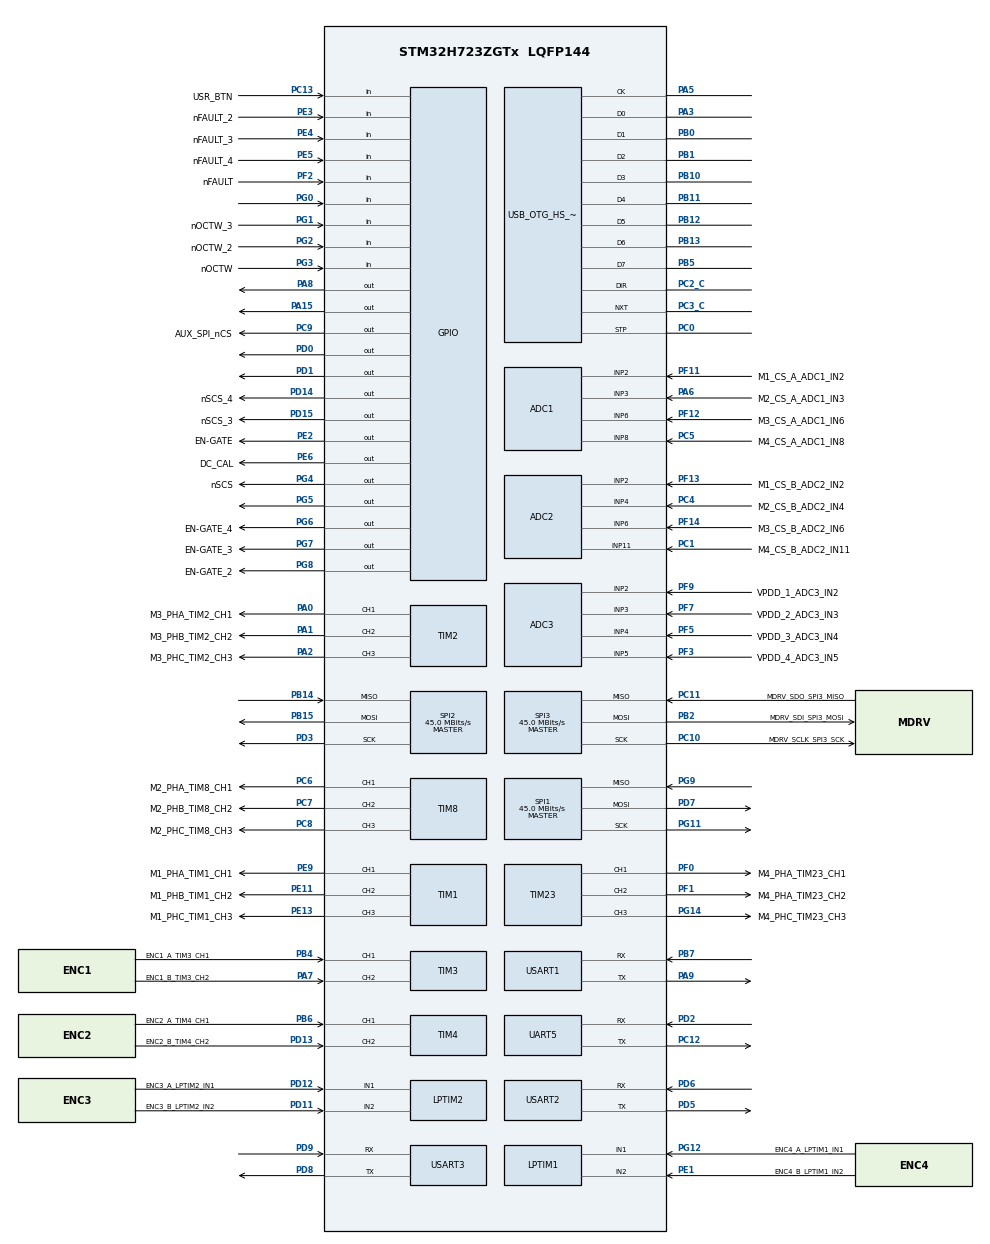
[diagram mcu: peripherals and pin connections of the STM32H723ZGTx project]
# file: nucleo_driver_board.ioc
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ADC1.Channel-0\#ChannelRegularConversion=ADC_CHANNEL_2
ADC1.ClockPrescaler=ADC_CLOCK_ASYNC_DIV4
ADC1.NbrOfConversionFlag=1
ADC1.OffsetNumber-0\#ChannelRegularConversion=ADC_OFFSET_NONE
ADC1.OffsetSignedSaturation-0\#ChannelRegularConversion=DISABLE
ADC1.Rank-0\#ChannelRegularConversion=1
ADC1.SamplingTime-0\#ChannelRegularConversion=ADC_SAMPLETIME_1CYCLE_5
ADC1.master=1
ADC2.Channel-4\#ChannelRegularConversion=ADC_CHANNEL_6
ADC2.ClockPrescaler=ADC_CLOCK_ASYNC_DIV4
ADC2.NbrOfConversionFlag=1
ADC2.OffsetNumber-4\#ChannelRegularConversion=ADC_OFFSET_NONE
ADC2.OffsetSignedSaturation-4\#ChannelRegularConversion=DISABLE
ADC2.Rank-4\#ChannelRegularConversion=1
ADC2.SamplingTime-4\#ChannelRegularConversion=ADC_SAMPLETIME_1CYCLE_5
ADC3.Channel-1\#ChannelRegularConversion=ADC_CHANNEL_2
ADC3.NbrOfConversionFlag=1
ADC3.OffsetNumber-1\#ChannelRegularConversion=ADC_OFFSET_NONE
ADC3.OffsetSign-1\#ChannelRegularConversion=ADC3_OFFSET_SIGN_NEGATIVE
ADC3.Rank-1\#ChannelRegularConversion=1
ADC3.SamplingTime-1\#ChannelRegularConversion=ADC3_SAMPLETIME_2CYCLES_5
Mcu.Family=STM32H7
Mcu.Name=STM32H723ZGTx
Mcu.Package=LQFP144
NVIC.OTG_HS_EP1_IN_IRQn=true\:0\:0\:false\:false\:true\:true\:true\:true
NVIC.OTG_HS_EP1_OUT_IRQn=true\:0\:0\:false\:false\:true\:true\:true\:true
NVIC.OTG_HS_IRQn=true\:0\:0\:false\:false\:true\:false\:true\:true
NVIC.PriorityGroup=NVIC_PRIORITYGROUP_4
PA0.GPIO_Label=M3_PHA_TIM2_CH1
PA0.Signal=S_TIM2_CH1_ETR
PA1.GPIO_Label=M3_PHB_TIM2_CH2
PA1.Signal=S_TIM2_CH2
PA13(JTMS/SWDIO).Mode=Trace_Asynchronous_SW
PA13(JTMS/SWDIO).Signal=DEBUG_JTMS-SWDIO
PA14(JTCK/SWCLK).Mode=Trace_Asynchronous_SW
PA14(JTCK/SWCLK).Signal=DEBUG_JTCK-SWCLK
PA15(JTDI).Signal=GPIO_Output
PA2.GPIO_Label=M3_PHC_TIM2_CH3
PA2.Signal=S_TIM2_CH3
PA3.Mode=Device_HS
PA3.Signal=USB_OTG_HS_ULPI_D0
PA5.Mode=Device_HS
PA5.Signal=USB_OTG_HS_ULPI_CK
PA6.GPIO_Label=M2_CS_A_ADC1_IN3
PA6.Signal=ADCx_INP3
PA7.GPIO_Label=ENC1_B_TIM3_CH2
PA7.Signal=S_TIM3_CH2
PA8.Signal=GPIO_Output
PA9.Mode=Asynchronous
PA9.Signal=USART1_TX
PB0.Mode=Device_HS
PB0.Signal=USB_OTG_HS_ULPI_D1
PB1.Mode=Device_HS
PB1.Signal=USB_OTG_HS_ULPI_D2
PB10.Mode=Device_HS
PB10.Signal=USB_OTG_HS_ULPI_D3
PB11.Mode=Device_HS
PB11.Signal=USB_OTG_HS_ULPI_D4
PB12.Mode=Device_HS
PB12.Signal=USB_OTG_HS_ULPI_D5
PB13.Mode=Device_HS
PB13.Signal=USB_OTG_HS_ULPI_D6
PB14.Mode=Full_Duplex_Master
PB14.Signal=SPI2_MISO
PB15.Mode=Full_Duplex_Master
PB15.Signal=SPI2_MOSI
PB2.GPIO_Label=MDRV_SDI_SPI3_MOSI
PB2.Mode=Full_Duplex_Master
PB2.Signal=SPI3_MOSI
PB3(JTDO/TRACESWO).Mode=Trace_Asynchronous_SW
PB3(JTDO/TRACESWO).Signal=DEBUG_JTDO-SWO
PB4(NJTRST).GPIO_Label=ENC1_A_TIM3_CH1
PB4(NJTRST).Signal=S_TIM3_CH1
PB5.Mode=Device_HS
PB5.Signal=USB_OTG_HS_ULPI_D7
PB6.GPIO_Label=ENC2_A_TIM4_CH1
PB6.Signal=S_TIM4_CH1
PB7.Mode=Asynchronous
PB7.Signal=USART1_RX
PC0.Mode=Device_HS
PC0.Signal=USB_OTG_HS_ULPI_STP
PC1.GPIO_Label=M4_CS_B_ADC2_IN11
PC1.Signal=ADCx_INP11
PC10.GPIO_Label=MDRV_SCLK_SPI3_SCK
PC10.Mode=Full_Duplex_Master
PC10.Signal=SPI3_SCK
PC11.GPIO_Label=MDRV_SDO_SPI3_MISO
PC11.Mode=Full_Duplex_Master
PC11.Signal=SPI3_MISO
PC12.Mode=Asynchronous
PC12.Signal=UART5_TX
PC13.GPIO_Label=USR_BTN
PC13.Signal=GPIO_Input
PC2_C.Mode=Device_HS
PC2_C.Signal=USB_OTG_HS_ULPI_DIR
PC3_C.Mode=Device_HS
PC3_C.Signal=USB_OTG_HS_ULPI_NXT
PC4.GPIO_Label=M2_CS_B_ADC2_IN4
PC4.Signal=ADCx_INP4
PC5.GPIO_Label=M4_CS_A_ADC1_IN8
PC5.Signal=ADCx_INP8
PC6.GPIO_Label=M2_PHA_TIM8_CH1
PC6.Signal=S_TIM8_CH1
PC7.GPIO_Label=M2_PHB_TIM8_CH2
PC7.Signal=S_TIM8_CH2
PC8.GPIO_Label=M2_PHC_TIM8_CH3
PC8.Signal=S_TIM8_CH3
PC9.GPIO_Label=AUX_SPI_nCS
PC9.Signal=GPIO_Output
PD0.Signal=GPIO_Output
PD1.Signal=GPIO_Output
PD11.GPIO_Label=ENC3_B_LPTIM2_IN2
PD11.Mode=Encoder_mode_occur1
PD11.Signal=LPTIM2_IN2
PD12.GPIO_Label=ENC3_A_LPTIM2_IN1
PD12.Mode=Encoder_mode_occur1
PD12.Signal=LPTIM2_IN1
PD13.GPIO_Label=ENC2_B_TIM4_CH2
PD13.Signal=S_TIM4_CH2
PD14.GPIO_Label=nSCS_4
PD14.Signal=GPIO_Output
PD15.GPIO_Label=nSCS_3
PD15.Signal=GPIO_Output
PD2.Mode=Asynchronous
PD2.Signal=UART5_RX
PD3.Mode=Full_Duplex_Master
PD3.Signal=SPI2_SCK
PD5.Mode=Asynchronous
PD5.Signal=USART2_TX
PD6.Mode=Asynchronous
PD6.Signal=USART2_RX
PD7.Mode=Full_Duplex_Master
PD7.Signal=SPI1_MOSI
PD8.Mode=Asynchronous
PD8.Signal=USART3_TX
PD9.Mode=Asynchronous
PD9.Signal=USART3_RX
PE1.GPIO_Label=ENC4_B_LPTIM1_IN2
PE1.Mode=Encoder_mode_occur1
PE1.Signal=LPTIM1_IN2
PE11.GPIO_Label=M1_PHB_TIM1_CH2
PE11.Signal=S_TIM1_CH2
PE13.GPIO_Label=M1_PHC_TIM1_CH3
PE13.Signal=S_TIM1_CH3
PE2.GPIO_Label=EN-GATE
PE2.Signal=GPIO_Output
PE3.GPIO_Label=nFAULT_2
PE3.Signal=GPIO_Input
PE4.GPIO_Label=nFAULT_3
PE4.Signal=GPIO_Input
PE5.GPIO_Label=nFAULT_4
PE5.Signal=GPIO_Input
PE6.GPIO_Label=DC_CAL
PE6.Signal=GPIO_Output
PE9.GPIO_Label=M1_PHA_TIM1_CH1
PE9.Signal=S_TIM1_CH1
PF0.GPIO_Label=M4_PHA_TIM23_CH1
PF0.Mode=PWM Generation1 CH1
PF0.Signal=TIM23_CH1
PF1.GPIO_Label=M4_PHA_TIM23_CH2
PF1.Signal=S_TIM23_CH2
PF11.GPIO_Label=M1_CS_A_ADC1_IN2
PF11.Mode=IN2-Single-Ended
PF11.Signal=ADC1_INP2
PF12.GPIO_Label=M3_CS_A_ADC1_IN6
PF12.Mode=IN6-Single-Ended
PF12.Signal=ADC1_INP6
PF13.GPIO_Label=M1_CS_B_ADC2_IN2
PF13.Mode=IN2-Single-Ended
PF13.Signal=ADC2_INP2
PF14.GPIO_Label=M3_CS_B_ADC2_IN6
PF14.Mode=IN6-Single-Ended
PF14.Signal=ADC2_INP6
PF2.GPIO_Label=nFAULT
PF2.Signal=GPIO_Input
PF3.GPIO_Label=VPDD_4_ADC3_IN5
PF3.Mode=IN5-Single-Ended
PF3.Signal=ADC3_INP5
PF5.GPIO_Label=VPDD_3_ADC3_IN4
PF5.Mode=IN4-Single-Ended
PF5.Signal=ADC3_INP4
PF7.GPIO_Label=VPDD_2_ADC3_IN3
PF7.Mode=IN3-Single-Ended
PF7.Signal=ADC3_INP3
PF9.GPIO_Label=VPDD_1_ADC3_IN2
PF9.Mode=IN2-Single-Ended
PF9.Signal=ADC3_INP2
PG0.Signal=GPIO_Input
PG1.GPIO_Label=nOCTW_3
PG1.Signal=GPIO_Input
PG11.Mode=Full_Duplex_Master
PG11.Signal=SPI1_SCK
PG12.GPIO_Label=ENC4_A_LPTIM1_IN1
PG12.Mode=Encoder_mode_occur1
PG12.Signal=LPTIM1_IN1
PG14.GPIO_Label=M4_PHC_TIM23_CH3
PG14.Signal=S_TIM23_CH3
PG2.GPIO_Label=nOCTW_2
PG2.Signal=GPIO_Input
PG3.GPIO_Label=nOCTW
PG3.Signal=GPIO_Input
PG4.GPIO_Label=nSCS
PG4.Signal=GPIO_Output
PG5.Signal=GPIO_Output
PG6.GPIO_Label=EN-GATE_4
PG6.Signal=GPIO_Output
PG7.GPIO_Label=EN-GATE_3
PG7.Signal=GPIO_Output
PG8.GPIO_Label=EN-GATE_2
PG8.Signal=GPIO_Output
PG9.Mode=Full_Duplex_Master
PG9.Signal=SPI1_MISO
ProjectManager.HeapSize=0x200
ProjectManager.StackSize=0x400
ProjectManager.TargetToolchain=Makefile
RCC.ADCFreq_Value=90000000
RCC.APB1Freq_Value=136000000
RCC.APB2Freq_Value=136000000
RCC.APB3Freq_Value=136000000
RCC.APB4Freq_Value=136000000
RCC.CortexFreq_Value=544000000
RCC.D1PPRE=RCC_APB3_DIV2
RCC.D2PPRE1=RCC_APB1_DIV2
RCC.D2PPRE2=RCC_APB2_DIV2
RCC.D3PPRE=RCC_APB4_DIV2
RCC.DIVM1=4
RCC.DIVM2=4
RCC.DIVN1=34
RCC.DIVN2=45
RCC.DIVP1=1
RCC.DIVP2=8
RCC.DIVQ1=3
RCC.HCLKFreq_Value=272000000
RCC.HPRE=RCC_HCLK_DIV2
RCC.LPTIM1CLockSelection=RCC_LPTIM1CLKSOURCE_PLL2
RCC.LPTIM2CLockSelection=RCC_LPTIM2CLKSOURCE_PLL2
RCC.PLL2FRACN=0
RCC.PLL3FRACN=0
RCC.PLLFRACN=0
RCC.RCC_MCO1Source=RCC_MCO1SOURCE_HSI48
RCC.RCC_MCODiv1=RCC_MCODIV_2
RCC.SPI123CLockSelection=RCC_SPI123CLKSOURCE_PLL2
RCC.SYSCLKFreq_VALUE=544000000
RCC.SYSCLKSource=RCC_SYSCLKSOURCE_PLLCLK
RCC.USART16CLockSelection=RCC_USART16910CLKSOURCE_HSI
RCC.USART234578CLockSelection=RCC_USART234578CLKSOURCE_HSI
RCC.USBCLockSelection=RCC_USBCLKSOURCE_HSI48
RCC.USBFreq_Value=48000000
SH.ADCx_INP11.0=ADC2_INP11,IN11-Single-Ended
SH.ADCx_INP3.0=ADC1_INP3,IN3-Single-Ended
SH.ADCx_INP4.0=ADC2_INP4,IN4-Single-Ended
SH.ADCx_INP8.0=ADC1_INP8,IN8-Single-Ended
SH.S_TIM1_CH1.0=TIM1_CH1,PWM Generation1 CH1
SH.S_TIM1_CH2.0=TIM1_CH2,PWM Generation2 CH2
SH.S_TIM1_CH3.0=TIM1_CH3,PWM Generation3 CH3
SH.S_TIM23_CH2.0=TIM23_CH2,PWM Generation2 CH2
SH.S_TIM23_CH3.0=TIM23_CH3,PWM Generation3 CH3
SH.S_TIM2_CH1_ETR.0=TIM2_CH1,PWM Generation1 CH1
SH.S_TIM2_CH2.0=TIM2_CH2,PWM Generation2 CH2
SH.S_TIM2_CH3.0=TIM2_CH3,PWM Generation3 CH3
SH.S_TIM3_CH1.0=TIM3_CH1,Encoder_Interface
SH.S_TIM3_CH2.0=TIM3_CH2,Encoder_Interface
SH.S_TIM4_CH1.0=TIM4_CH1,Encoder_Interface
SH.S_TIM4_CH2.0=TIM4_CH2,Encoder_Interface
SH.S_TIM8_CH1.0=TIM8_CH1,PWM Generation1 CH1
SH.S_TIM8_CH2.0=TIM8_CH2,PWM Generation2 CH2
SH.S_TIM8_CH3.0=TIM8_CH3,PWM Generation3 CH3
SPI1.BaudRatePrescaler=SPI_BAUDRATEPRESCALER_2
SPI1.CalculateBaudRate=45.0 MBits/s
SPI1.Direction=SPI_DIRECTION_2LINES
SPI1.Mode=SPI_MODE_MASTER
SPI1.VirtualType=VM_MASTER
SPI2.BaudRatePrescaler=SPI_BAUDRATEPRESCALER_2
SPI2.CalculateBaudRate=45.0 MBits/s
SPI2.Direction=SPI_DIRECTION_2LINES
SPI2.Mode=SPI_MODE_MASTER
SPI2.VirtualType=VM_MASTER
SPI3.BaudRatePrescaler=SPI_BAUDRATEPRESCALER_2
SPI3.CalculateBaudRate=45.0 MBits/s
SPI3.Direction=SPI_DIRECTION_2LINES
SPI3.Mode=SPI_MODE_MASTER
SPI3.VirtualType=VM_MASTER
TIM1.Channel-PWM\ Generation1\ CH1=TIM_CHANNEL_1
TIM1.Channel-PWM\ Generation2\ CH2=TIM_CHANNEL_2
TIM1.Channel-PWM\ Generation3\ CH3=TIM_CHANNEL_3
TIM2.Channel-PWM\ Generation1\ CH1=TIM_CHANNEL_1
TIM2.Channel-PWM\ Generation2\ CH2=TIM_CHANNEL_2
TIM2.Channel-PWM\ Generation3\ CH3=TIM_CHANNEL_3
TIM23.Channel-PWM\ Generation1\ CH1=TIM_CHANNEL_1
TIM23.Channel-PWM\ Generation2\ CH2=TIM_CHANNEL_2
TIM23.Channel-PWM\ Generation3\ CH3=TIM_CHANNEL_3
TIM3.EncoderMode=TIM_ENCODERMODE_TI12
TIM4.EncoderMode=TIM_ENCODERMODE_TI12
TIM8.Channel-PWM\ Generation1\ CH1=TIM_CHANNEL_1
TIM8.Channel-PWM\ Generation2\ CH2=TIM_CHANNEL_2
TIM8.Channel-PWM\ Generation3\ CH3=TIM_CHANNEL_3
USART1.VirtualMode-Asynchronous=VM_ASYNC
USART2.VirtualMode-Asynchronous=VM_ASYNC
USART3.VirtualMode-Asynchronous=VM_ASYNC
USB_DEVICE.CLASS_NAME_HS=CDC
USB_DEVICE.CONFIGURATION_STRING_CDC_HS=CDC Servos
USB_DEVICE.INTERFACE_STRING_CDC_HS=CDC Servo Interface
USB_DEVICE.MANUFACTURER_STRING=Copper280z
USB_DEVICE.PRODUCT_STRING_CDC_HS=WOOO SERVOS
USB_DEVICE.VirtualMode=Cdc
USB_DEVICE.VirtualModeHS=Cdc_HS
USB_OTG_HS.Sof_enable-Device_HS=DISABLE
USB_OTG_HS.VirtualMode-Device_HS=Device_HS
USB_OTG_HS.dma_enable-Device_HS=DISABLE
USB_OTG_HS.lpm_enable-Device_HS=DISABLE
VP_USB_DEVICE_VS_USB_DEVICE_CDC_HS.Mode=CDC_HS
board=custom

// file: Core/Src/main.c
/* USER CODE BEGIN Header */
/**
  ******************************************************************************
  * @file           : main.c
  * @brief          : Main program body
  ******************************************************************************
  * @attention
  *
  * Copyright (c) 2024 STMicroelectronics.
  * All rights reserved.
  *
  * This software is licensed under terms that can be found in the LICENSE file
  * in the root directory of this software component.
  * If no LICENSE file comes with this software, it is provided AS-IS.
  *
  ******************************************************************************
  */
/* USER CODE END Header */
#include "main.h"
#include "adc.h"
#include "lptim.h"
#include "spi.h"
#include "tim.h"
#include "usart.h"
#include "usb_device.h"
#include "gpio.h"
#include "usbd_cdc_if.h"

/* USER CODE BEGIN Includes */
USBD_HandleTypeDef USBD_Device;
/* USER CODE END Includes */

void SystemClock_Config(void);
void PeriphCommonClock_Config(void);

int main(void)
{

  /* MCU Configuration--------------------------------------------------------*/

  /* Reset of all peripherals, Initializes the Flash interface and the Systick. */
  HAL_Init();

  /* Configure the system clock */
  SystemClock_Config();

/* Configure the peripherals common clocks */
  PeriphCommonClock_Config();

  /* Initialize all configured peripherals */
  MX_GPIO_Init();
  MX_ADC1_Init();
  MX_ADC2_Init();
  MX_TIM1_Init();
  MX_TIM8_Init();
  MX_SPI3_Init();
  MX_TIM3_Init();
  MX_TIM4_Init();
  MX_ADC3_Init();
  MX_LPTIM1_Init();
  MX_LPTIM2_Init();
  MX_SPI1_Init();
  MX_SPI2_Init();
  MX_TIM2_Init();
  MX_TIM23_Init();
  MX_UART5_Init();
  MX_USART1_UART_Init();
  MX_USART2_UART_Init();
  MX_USART3_UART_Init();
  MX_USB_DEVICE_Init();

  char buf[2048] = "Hello World!\n***********************************************************************************************************************************************************************************************************************************************************************************************************************************************************************************************************************************";

  /* Infinite loop */
  while (1)
  {
    CDC_Transmit_HS((uint8_t*)buf, 2048);

  }
}

void SystemClock_Config(void)
{
  RCC_OscInitTypeDef RCC_OscInitStruct = {0};
  RCC_ClkInitTypeDef RCC_ClkInitStruct = {0};

  /** Supply configuration update enable
  */
  HAL_PWREx_ConfigSupply(PWR_LDO_SUPPLY);

  /** Configure the main internal regulator output voltage
  */
  __HAL_PWR_VOLTAGESCALING_CONFIG(PWR_REGULATOR_VOLTAGE_SCALE0);

  while(!__HAL_PWR_GET_FLAG(PWR_FLAG_VOSRDY)) {}

  /** Initializes the RCC Oscillators according to the specified parameters
  * in the RCC_OscInitTypeDef structure.
  */
  RCC_OscInitStruct.OscillatorType = RCC_OSCILLATORTYPE_HSI48|RCC_OSCILLATORTYPE_HSI;
  RCC_OscInitStruct.HSIState = RCC_HSI_DIV1;
  RCC_OscInitStruct.HSICalibrationValue = 64;
  RCC_OscInitStruct.HSI48State = RCC_HSI48_ON;
  RCC_OscInitStruct.PLL.PLLState = RCC_PLL_ON;
  RCC_OscInitStruct.PLL.PLLSource = RCC_PLLSOURCE_HSI;
  RCC_OscInitStruct.PLL.PLLM = 4;
  RCC_OscInitStruct.PLL.PLLN = 34;
  RCC_OscInitStruct.PLL.PLLP = 1;
  RCC_OscInitStruct.PLL.PLLQ = 3;
  RCC_OscInitStruct.PLL.PLLR = 2;
  RCC_OscInitStruct.PLL.PLLRGE = RCC_PLL1VCIRANGE_3;
  RCC_OscInitStruct.PLL.PLLVCOSEL = RCC_PLL1VCOWIDE;
  RCC_OscInitStruct.PLL.PLLFRACN = 0;
  if (HAL_RCC_OscConfig(&RCC_OscInitStruct) != HAL_OK)
  {
    Error_Handler();
  }

  /** Initializes the CPU, AHB and APB buses clocks
  */
  RCC_ClkInitStruct.ClockType = RCC_CLOCKTYPE_HCLK|RCC_CLOCKTYPE_SYSCLK
                              |RCC_CLOCKTYPE_PCLK1|RCC_CLOCKTYPE_PCLK2
                              |RCC_CLOCKTYPE_D3PCLK1|RCC_CLOCKTYPE_D1PCLK1;
  RCC_ClkInitStruct.SYSCLKSource = RCC_SYSCLKSOURCE_PLLCLK;
  RCC_ClkInitStruct.SYSCLKDivider = RCC_SYSCLK_DIV1;
  RCC_ClkInitStruct.AHBCLKDivider = RCC_HCLK_DIV2;
  RCC_ClkInitStruct.APB3CLKDivider = RCC_APB3_DIV2;
  RCC_ClkInitStruct.APB1CLKDivider = RCC_APB1_DIV2;
  RCC_ClkInitStruct.APB2CLKDivider = RCC_APB2_DIV2;
  RCC_ClkInitStruct.APB4CLKDivider = RCC_APB4_DIV2;

  if (HAL_RCC_ClockConfig(&RCC_ClkInitStruct, FLASH_LATENCY_3) != HAL_OK)
  {
    Error_Handler();
  }
}

void PeriphCommonClock_Config(void)
{
  RCC_PeriphCLKInitTypeDef PeriphClkInitStruct = {0};

  /** Initializes the peripherals clock
  */
  PeriphClkInitStruct.PeriphClockSelection = RCC_PERIPHCLK_ADC|RCC_PERIPHCLK_LPTIM1
                              |RCC_PERIPHCLK_LPTIM2|RCC_PERIPHCLK_SPI3
                              |RCC_PERIPHCLK_SPI2|RCC_PERIPHCLK_SPI1;
  PeriphClkInitStruct.PLL2.PLL2M = 4;
  PeriphClkInitStruct.PLL2.PLL2N = 45;
  PeriphClkInitStruct.PLL2.PLL2P = 8;
  PeriphClkInitStruct.PLL2.PLL2Q = 2;
  PeriphClkInitStruct.PLL2.PLL2R = 2;
  PeriphClkInitStruct.PLL2.PLL2RGE = RCC_PLL2VCIRANGE_3;
  PeriphClkInitStruct.PLL2.PLL2VCOSEL = RCC_PLL2VCOWIDE;
  PeriphClkInitStruct.PLL2.PLL2FRACN = 0;
  PeriphClkInitStruct.Spi123ClockSelection = RCC_SPI123CLKSOURCE_PLL2;
  PeriphClkInitStruct.Lptim1ClockSelection = RCC_LPTIM1CLKSOURCE_PLL2;
  PeriphClkInitStruct.Lptim2ClockSelection = RCC_LPTIM2CLKSOURCE_PLL2;
  PeriphClkInitStruct.AdcClockSelection = RCC_ADCCLKSOURCE_PLL2;
  if (HAL_RCCEx_PeriphCLKConfig(&PeriphClkInitStruct) != HAL_OK)
  {
    Error_Handler();
  }
}

void Error_Handler(void)
{
  __disable_irq();
  while (1)
  {
  }
}
